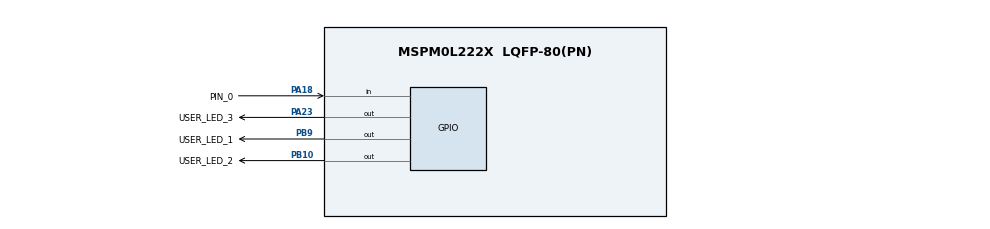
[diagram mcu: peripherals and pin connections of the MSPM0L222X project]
// @cliArgs --device "MSPM0L222X" --package "LQFP-80(PN)" --part "Default"
// @cliArgs --board /ti/boards/LP_MSPM0L2228 --rtos nortos

/**
 * Import the modules used in this configuration.
 */
const ProjectConfig = scripting.addModule("/ti/project_config/ProjectConfig");
const AESADV        = scripting.addModule("/ti/driverlib/AESADV");
const Board         = scripting.addModule("/ti/driverlib/Board", {}, false);
const SECCONFIG     = scripting.addModule("/ti/driverlib/SECCONFIG");
const GPIO          = scripting.addModule("/ti/driverlib/GPIO", {}, false);
const GPIO1         = GPIO.addInstance();
const GPIO2         = GPIO.addInstance();
const SYSCTL        = scripting.addModule("/ti/driverlib/SYSCTL", {}, false);

/**
 * Write custom configuration values to the imported modules.
 */
ProjectConfig.genDisable = true;

SECCONFIG.cscPrereqAck        = true;
SECCONFIG.developmentOptions  = ["enablePseudoRandom"];
SECCONFIG.cscBankSize         = 0x20000;
SECCONFIG.cscSecretAddress    = 0x4000;
SECCONFIG.cscSecretSize       = 0x400;
SECCONFIG.cscLockStorageSize  = 0x400;
SECCONFIG.cscAppImageBaseAddr = 0x4800;
SECCONFIG.cscAppImageSize     = 0x2800;

GPIO1.$name                         = "GPIO_LEDS";
GPIO1.associatedPins.create(3);
GPIO1.associatedPins[0].$name       = "USER_LED_1";
GPIO1.associatedPins[0].pin.$assign = "PB9";
GPIO1.associatedPins[1].$name       = "USER_LED_2";
GPIO1.associatedPins[1].pin.$assign = "PB10";
GPIO1.associatedPins[2].$name       = "USER_LED_3";
GPIO1.associatedPins[2].pin.$assign = "PA23";

GPIO2.$name                              = "GPIO_SWITCHES";
GPIO2.associatedPins[0].$name            = "PIN_0";
GPIO2.associatedPins[0].internalResistor = "PULL_DOWN";
GPIO2.associatedPins[0].direction        = "INPUT";
GPIO2.associatedPins[0].inputFilter      = "3_CYCLES";
GPIO2.associatedPins[0].interruptEn      = true;
GPIO2.associatedPins[0].polarity         = "RISE";
GPIO2.associatedPins[0].pin.$assign      = "PA18";
